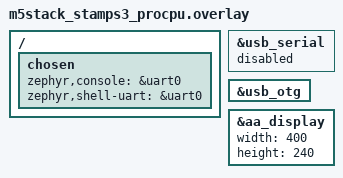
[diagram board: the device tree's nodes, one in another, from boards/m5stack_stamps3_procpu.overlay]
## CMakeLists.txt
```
# Copyright The Zephyr Project Contributors
# SPDX-License-Identifier: Apache-2.0

cmake_minimum_required(VERSION 3.28.0)
find_package(Zephyr REQUIRED HINTS $ENV{ZEPHYR_BASE})
project(android_auto)

include(${ZEPHYR_BASE}/samples/subsys/usb/common/common.cmake)

list(APPEND CMAKE_MODULE_PATH ${ZEPHYR_BASE}/modules/nanopb)
include(nanopb)

zephyr_nanopb_sources(app src/aa.proto)

target_sources(app PRIVATE
  src/aa_control.c
  src/aa_display.c
  src/aa_encoder.c
  src/aa_frame.c
  src/aa_input.c
  src/aa_session.c
  src/aa_tls.c
  src/aa_touch.c
  src/aa_video.c
  src/h264_ipcm.c
  src/main.c
  src/ui.c
  src/yuv.c
)

target_sources_ifdef(CONFIG_SAMPLE_AA_TRANSPORT_USB app PRIVATE
  src/aa_aoa.c
  src/aa_transport_usb.c
)
target_sources_ifdef(CONFIG_SAMPLE_AA_TRANSPORT_TCP app PRIVATE src/aa_transport_tcp.c)
target_sources_ifdef(CONFIG_SAMPLE_AA_SENSOR_CHANNEL app PRIVATE src/aa_sensor.c)

if(CONFIG_SAMPLE_AA_H264_DUMP)
  target_sources(app PRIVATE src/h264_dump.c)
  target_sources(native_simulator INTERFACE src/h264_dump_bottom.c)
endif()

# Embed the PEM credentials, NUL terminated by the including source file
set(gen_dir ${ZEPHYR_BINARY_DIR}/include/generated)
foreach(cred cert key)
  string(TOUPPER ${cred} cred_upper)
  set(cred_path "${CONFIG_SAMPLE_AA_${cred_upper}_FILE}")
  if(NOT IS_ABSOLUTE "${cred_path}")
    set(cred_path "${CMAKE_CURRENT_SOURCE_DIR}/${cred_path}")
  endif()
  generate_inc_file_for_target(app ${cred_path} ${gen_dir}/aa_${cred}.pem.inc)
endforeach()

if(CONFIG_SAMPLE_AA_DEMO_WIDGETS)
  set(LVGL_DIR ${ZEPHYR_LVGL_MODULE_DIR})
  target_include_directories(app PRIVATE ${LVGL_DIR}/demos/)
  target_sources(app PRIVATE
    ${LVGL_DIR}/demos/widgets/assets/img_clothes.c
    ${LVGL_DIR}/demos/widgets/assets/img_demo_widgets_avatar.c
    ${LVGL_DIR}/demos/widgets/assets/img_demo_widgets_needle.c
    ${LVGL_DIR}/demos/widgets/assets/img_lvgl_logo.c
    ${LVGL_DIR}/demos/widgets/lv_demo_widgets.c
    ${LVGL_DIR}/demos/widgets/lv_demo_widgets_analytics.c
    ${LVGL_DIR}/demos/widgets/lv_demo_widgets_components.c
    ${LVGL_DIR}/demos/widgets/lv_demo_widgets_profile.c
    ${LVGL_DIR}/demos/widgets/lv_demo_widgets_shop.c
  )
endif()
```

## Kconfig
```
# Copyright The Zephyr Project Contributors
# SPDX-License-Identifier: Apache-2.0

mainmenu "Android Auto accessory sample"

source "samples/subsys/usb/common/Kconfig.sample_usbd"

menu "Android Auto sample"

choice SAMPLE_AA_TRANSPORT
	prompt "Head unit transport"
	default SAMPLE_AA_TRANSPORT_USB if USB_DEVICE_STACK_NEXT
	default SAMPLE_AA_TRANSPORT_TCP

config SAMPLE_AA_TRANSPORT_USB
	bool "USB accessory"
	depends on USB_DEVICE_STACK_NEXT
	help
	  Enumerate as an Android device in accessory mode and talk to the head
	  unit over the accessory bulk endpoints.

config SAMPLE_AA_TRANSPORT_TCP
	bool "TCP"
	depends on NET_SOCKETS
	help
	  Wait for a head unit on a TCP port instead of USB. The Desktop Head
	  Unit of the Android SDK connects to localhost:5277 by default.

endchoice

config SAMPLE_AA_TCP_PORT
	int "TCP port"
	depends on SAMPLE_AA_TRANSPORT_TCP
	default 5277
	range 0 65535
	help
	  Port the head unit connects to. 0 lets the host pick a free port,
	  which is logged at startup.

if SAMPLE_AA_TRANSPORT_USB

config SAMPLE_AA_AOA_VID
	hex "Accessory mode vendor id"
	default 0x18d1
	help
	  Vendor id presented in accessory mode. Head units look for Google's
	  vendor id and the accessory product ids.

config SAMPLE_AA_AOA_PID
	hex "Accessory mode product id"
	default 0x2d00
	help
	  0x2d00 is accessory mode alone, 0x2d01 accessory mode with an ADB
	  interface, which this sample does not provide.

choice SAMPLE_AA_USB_START_MODE
	prompt "Accessory mode entry"
	default SAMPLE_AA_USB_ACCESSORY_AT_BOOT

config SAMPLE_AA_USB_ACCESSORY_AT_BOOT
	bool "Enumerate in accessory mode"
	help
	  Present the accessory vendor and product ids from the first
	  enumeration. A start request from the head unit still triggers a
	  re-enumeration.

config SAMPLE_AA_USB_ACCESSORY_ON_START
	bool "Enumerate with the Zephyr ids and switch on request"
	help
	  Enumerate with CONFIG_SAMPLE_USBD_VID and CONFIG_SAMPLE_USBD_PID and
	  only switch to the accessory ids when the head unit sends the
	  accessory start request, like an Android device does.

endchoice

config SAMPLE_AA_AOA_STRING_SIZE
	int "Accessory string buffer size"
	default 64
	range 8 256

config SAMPLE_AA_AOA_SWITCH_DELAY_MS
	int "Delay before re-enumerating after a start request (ms)"
	default 100

config SAMPLE_AA_USB_OUT_XFER_SIZE
	int "Bulk OUT transfer size"
	default 512
	range 64 4096

config SAMPLE_AA_USB_IN_XFER_SIZE
	int "Bulk IN transfer size"
	default 2048
	range 64 8192

config SAMPLE_AA_USB_RX_PIPE_SIZE
	int "Receive pipe size"
	default 8192

config SAMPLE_AA_USB_WRITE_TIMEOUT_MS
	int "Bulk IN buffer wait timeout (ms)"
	default 2000

config SAMPLE_AA_USB_START_DELAY_MS
	int "Delay before the USB device is enabled (ms)"
	default 0
	help
	  On SoCs whose USB PHY is shared between a serial or JTAG debug port
	  and the USB device controller, the debug port disappears once the
	  device is enabled. A delay keeps it reachable after every reset,
	  which leaves a window to enter the bootloader for reflashing.

endif # SAMPLE_AA_TRANSPORT_USB

config SAMPLE_AA_TX_CHUNK_SIZE
	int "Largest message fragment sent (bytes)"
	default 16384
	range 1024 16384
	help
	  Messages larger than this are fragmented. Must not exceed the Mbed
	  TLS output content length.

config SAMPLE_AA_RX_FRAME_SIZE
	int "Receive frame buffer size (bytes)"
	default 8256
	help
	  Must hold the largest TLS record the head unit sends, that is the
	  Mbed TLS input content length plus the record overhead.

config SAMPLE_AA_RX_MSG_SIZE
	int "Reassembly buffer for fragmented messages (bytes)"
	default 4096

config SAMPLE_AA_SESSION_TIMEOUT_MS
	int "Session setup timeout (ms)"
	default 20000
	help
	  The link is dropped when the session does not reach the running
	  state within this time.

config SAMPLE_AA_PROTO_MINOR
	int "Protocol minor version announced to the head unit"
	default 1

config SAMPLE_AA_DEVICE_NAME
	string "Device name announced in service discovery"
	default "Zephyr"

config SAMPLE_AA_DEVICE_BRAND
	string "Device brand announced in service discovery"
	default "Zephyr Project"

config SAMPLE_AA_RX_THREAD_PRIORITY
	int "Receive thread priority"
	default 5

config SAMPLE_AA_RX_STACK_SIZE
	int "Receive thread stack size"
	default 8192 if 64BIT
	default 6144

config SAMPLE_AA_VIDEO_THREAD_PRIORITY
	int "Video thread priority"
	default 7

config SAMPLE_AA_VIDEO_STACK_SIZE
	int "Video thread stack size"
	default 8192 if 64BIT
	default 4096

config SAMPLE_AA_INPUT_KEYS
	bool "Bind head unit keys and report them as input key events"
	default y

config SAMPLE_AA_SENSOR_CHANNEL
	bool "Subscribe to the night mode sensor and switch the theme"

config SAMPLE_AA_CERT_FILE
	string "Certificate presented to the head unit (PEM)"
	default "certs/aa_cert.pem"
	help
	  Relative paths are resolved from the sample directory. Head units
	  that verify the phone certificate need a certificate issued by
	  Google; the bundled one is self-signed.

config SAMPLE_AA_KEY_FILE
	string "Private key of the certificate (PEM)"
	default "certs/aa_key.pem"

config SAMPLE_AA_TLS_DEBUG_LEVEL
	int "Mbed TLS debug threshold"
	depends on MBEDTLS_DEBUG
	default 1
	range 0 5

menu "Video"

choice SAMPLE_AA_VIDEO_RESOLUTION
	prompt "Stream resolution"
	default SAMPLE_AA_VIDEO_800X480

config SAMPLE_AA_VIDEO_800X480
	bool "800x480"

config SAMPLE_AA_VIDEO_1280X720
	bool "1280x720"

endchoice

config SAMPLE_AA_VIDEO_WIDTH
	int
	default 1280 if SAMPLE_AA_VIDEO_1280X720
	default 800

config SAMPLE_AA_VIDEO_HEIGHT
	int
	default 720 if SAMPLE_AA_VIDEO_1280X720
	default 480

choice SAMPLE_AA_VIDEO_FPS
	prompt "Frame rate requested from the head unit"
	default SAMPLE_AA_VIDEO_FPS_30

config SAMPLE_AA_VIDEO_FPS_30
	bool "30 fps"

config SAMPLE_AA_VIDEO_FPS_60
	bool "60 fps"

endchoice

config SAMPLE_AA_MAX_FPS
	int "Maximum number of pictures sent per second"
	default 30
	range 1 60

config SAMPLE_AA_MAX_MBS_PER_FRAME
	int "Maximum coded macroblocks per P picture (0 = unlimited)"
	default 0
	help
	  Large redraws are spread over several pictures instead of one long
	  transfer when this is set.

config SAMPLE_AA_MAX_KBPS
	int "Output rate cap in kbit/s (0 = link speed)"
	default 0

config SAMPLE_AA_VIDEO_MAX_UNACKED_CAP
	int "Upper bound for unacknowledged media messages"
	default 4
	range 1 16

config SAMPLE_AA_VIDEO_ACK_TIMEOUT_MS
	int "Media acknowledgment timeout (ms)"
	default 3000

config SAMPLE_AA_VIDEO_CODEC_CONFIG_MSG
	bool "Send the parameter sets in a separate media message first"
	help
	  The parameter sets are always part of every IDR picture; this
	  additionally sends them once in a media message without timestamp
	  when streaming starts.

config SAMPLE_AA_H264_LEVEL_IDC
	int "H.264 level_idc"
	default 31

config SAMPLE_AA_H264_SLICE_ROWS
	int "Macroblock rows per slice (0 = one slice per picture)"
	default 1
	range 0 68

config SAMPLE_AA_H264_OUT_BUF_SIZE
	int "Encoder staging buffer (bytes)"
	default 2048
	range 256 16384

config SAMPLE_AA_DIRTY_COMPARE
	bool "Only send macroblocks whose pixels changed"
	default y
	help
	  Compare the rendered pixels with the framebuffer before marking a
	  macroblock dirty. LVGL redraws whole areas; the comparison keeps
	  unchanged macroblocks off the link.

choice SAMPLE_AA_PIXEL_FORMAT
	prompt "Framebuffer pixel format"
	default SAMPLE_AA_PIXEL_RGB565

config SAMPLE_AA_PIXEL_RGB565
	bool "RGB565"
	depends on LV_COLOR_DEPTH_16

config SAMPLE_AA_PIXEL_L8
	bool "8-bit grayscale"
	depends on LV_COLOR_DEPTH_8
	help
	  Halves the framebuffer size at the cost of colour, for boards
	  without external RAM.

endchoice

config SAMPLE_AA_FB_IN_EXT_RAM
	bool "Place the framebuffer in external RAM"
	depends on ESP_SPIRAM
	default y

config SAMPLE_AA_FB_SECTION
	string "Framebuffer linker section"
	depends on SAMPLE_AA_FB_IN_EXT_RAM
	default ".ext_ram.bss"

config SAMPLE_AA_H264_DUMP
	bool "Dump the stream and reference pictures to host files"
	depends on ARCH_POSIX
	help
	  Writes the H.264 stream and, for every picture, the framebuffer as
	  I420 so that a host decoder can be checked for bit-exact output.

config SAMPLE_AA_H264_DUMP_PATH
	string "H.264 dump file"
	depends on SAMPLE_AA_H264_DUMP
	default "aa_video.h264"

config SAMPLE_AA_H264_SELFTEST
	bool "Encode and check a few pictures at boot"

config SAMPLE_AA_DEMO_WIDGETS
	bool "Show the LVGL widgets demo instead of the sample screen"
	select LV_USE_DEMO_WIDGETS
	select LV_FONT_MONTSERRAT_12
	select LV_FONT_MONTSERRAT_14
	select LV_FONT_MONTSERRAT_16
	select LV_FONT_MONTSERRAT_18
	select LV_FONT_MONTSERRAT_20
	select LV_FONT_MONTSERRAT_22
	select LV_FONT_MONTSERRAT_24

endmenu # Video

module = SAMPLE_AA
module-str = Android Auto sample
source "subsys/logging/Kconfig.template.log_config"

endmenu # Android Auto sample

source "Kconfig.zephyr"
```

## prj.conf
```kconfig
CONFIG_LOG=y
CONFIG_MAIN_STACK_SIZE=4096

CONFIG_INPUT=y
CONFIG_DISPLAY=y

CONFIG_LVGL=y
CONFIG_LV_Z_MEM_POOL_SIZE=32768
CONFIG_LV_Z_VDB_SIZE=10
CONFIG_LV_Z_RUN_LVGL_ON_WORKQUEUE=y
CONFIG_LV_Z_LVGL_MUTEX=y
CONFIG_LV_Z_LVGL_WORKQUEUE_STACK_SIZE=8192
CONFIG_LV_FONT_MONTSERRAT_14=y
CONFIG_LV_FONT_MONTSERRAT_24=y
CONFIG_LV_USE_THEME_DEFAULT=y

CONFIG_PSA_CRYPTO=y
CONFIG_MBEDTLS=y
CONFIG_MBEDTLS_ENABLE_HEAP=y
CONFIG_MBEDTLS_HEAP_SIZE=49152
CONFIG_MBEDTLS_CIPHERSUITE_TLS_ECDHE_ECDSA_WITH_AES_128_GCM_SHA256=y
CONFIG_MBEDTLS_SSL_IN_CONTENT_LEN=8192
CONFIG_MBEDTLS_SSL_OUT_CONTENT_LEN=16384
CONFIG_MBEDTLS_PEM_PARSE_C=y
CONFIG_MBEDTLS_ECP_NIST_OPTIM=y
CONFIG_ENTROPY_GENERATOR=y

CONFIG_NANOPB=y
```

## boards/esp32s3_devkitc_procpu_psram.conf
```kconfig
CONFIG_USB_DEVICE_STACK_NEXT=y
CONFIG_SAMPLE_AA_TRANSPORT_USB=y
CONFIG_SAMPLE_USBD_PID=0x0014
CONFIG_SAMPLE_USBD_PRODUCT="Android Auto accessory"
CONFIG_USBD_LOG_LEVEL_WRN=y
CONFIG_UDC_DRIVER_LOG_LEVEL_WRN=y

CONFIG_SAMPLE_AA_TX_CHUNK_SIZE=8192
CONFIG_SAMPLE_AA_RX_FRAME_SIZE=4160
CONFIG_MBEDTLS_SSL_OUT_CONTENT_LEN=8192
CONFIG_MBEDTLS_SSL_IN_CONTENT_LEN=4096
CONFIG_MBEDTLS_HEAP_SIZE=40960

# External RAM holds the full-resolution framebuffer and the LVGL buffers
CONFIG_ESP_SPIRAM=y
CONFIG_LV_Z_VDB_CUSTOM_SECTION=y
CONFIG_LV_Z_MEMORY_POOL_CUSTOM_SECTION=y
CONFIG_LV_Z_MEM_POOL_SIZE=131072
CONFIG_LV_Z_VDB_SIZE=10
CONFIG_SPIRAM_MODE_QUAD=y
```

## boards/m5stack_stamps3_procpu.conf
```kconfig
CONFIG_USB_DEVICE_STACK_NEXT=y
CONFIG_SAMPLE_AA_TRANSPORT_USB=y
CONFIG_SAMPLE_USBD_PID=0x0014
CONFIG_SAMPLE_USBD_PRODUCT="Android Auto accessory"
CONFIG_USBD_LOG_LEVEL_WRN=y
CONFIG_UDC_DRIVER_LOG_LEVEL_WRN=y

CONFIG_SAMPLE_AA_TX_CHUNK_SIZE=8192
CONFIG_SAMPLE_AA_RX_FRAME_SIZE=4160
CONFIG_MBEDTLS_SSL_OUT_CONTENT_LEN=8192
CONFIG_MBEDTLS_SSL_IN_CONTENT_LEN=4096
CONFIG_MBEDTLS_HEAP_SIZE=40960

# No external RAM: half-resolution grayscale framebuffer (see the README)
CONFIG_LV_COLOR_DEPTH_8=y
CONFIG_SAMPLE_AA_PIXEL_L8=y
CONFIG_LV_Z_MEM_POOL_SIZE=32768
CONFIG_LV_Z_VDB_SIZE=10
```

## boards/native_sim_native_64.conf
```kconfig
CONFIG_SAMPLE_AA_TRANSPORT_TCP=y

CONFIG_NETWORKING=y
CONFIG_NET_IPV4=y
CONFIG_NET_IPV6=n
CONFIG_NET_SOCKETS=y
CONFIG_NET_SOCKETS_OFFLOAD=y
CONFIG_NET_DRIVERS=y
CONFIG_NET_NATIVE_OFFLOADED_SOCKETS=y
CONFIG_ETH_NATIVE_TAP=n

CONFIG_MBEDTLS_HEAP_SIZE=65536
CONFIG_LV_Z_MEM_POOL_SIZE=131072
CONFIG_LV_Z_VDB_SIZE=25
```

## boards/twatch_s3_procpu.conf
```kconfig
CONFIG_USB_DEVICE_STACK_NEXT=y
CONFIG_SAMPLE_AA_TRANSPORT_USB=y
CONFIG_SAMPLE_USBD_PID=0x0014
CONFIG_SAMPLE_USBD_PRODUCT="Android Auto accessory"
CONFIG_USBD_LOG_LEVEL_WRN=y
CONFIG_UDC_DRIVER_LOG_LEVEL_WRN=y

CONFIG_SAMPLE_AA_TX_CHUNK_SIZE=8192
CONFIG_SAMPLE_AA_RX_FRAME_SIZE=4160
CONFIG_MBEDTLS_SSL_OUT_CONTENT_LEN=8192
CONFIG_MBEDTLS_SSL_IN_CONTENT_LEN=4096
CONFIG_MBEDTLS_HEAP_SIZE=40960

# External RAM holds the full-resolution framebuffer and the LVGL buffers
CONFIG_ESP_SPIRAM=y
CONFIG_LV_Z_VDB_CUSTOM_SECTION=y
CONFIG_LV_Z_MEMORY_POOL_CUSTOM_SECTION=y
CONFIG_LV_Z_MEM_POOL_SIZE=131072
CONFIG_LV_Z_VDB_SIZE=10
CONFIG_SPIRAM_MODE_OCT=y
CONFIG_LV_COLOR_16_SWAP=n

# The USB serial console shares the PHY with USB OTG: keep it for a few seconds after
# reset so that the boot log is visible and the bootloader stays reachable for flashing
CONFIG_SAMPLE_AA_USB_START_DELAY_MS=8000
```

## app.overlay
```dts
/*
 * Copyright The Zephyr Project Contributors
 * SPDX-License-Identifier: Apache-2.0
 */

#include <android_auto.dtsi>
```

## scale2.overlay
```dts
/*
 * Copyright The Zephyr Project Contributors
 * SPDX-License-Identifier: Apache-2.0
 */

/* Render at half the stream resolution, every pixel becomes a 2x2 block */
&aa_display {
	width = <400>;
	height = <240>;
};
```

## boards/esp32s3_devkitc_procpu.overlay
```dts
/*
 * Copyright The Zephyr Project Contributors
 * SPDX-License-Identifier: Apache-2.0
 */

#include <android_auto.dtsi>

/* Half-resolution framebuffer, every pixel becomes a 2x2 block in the stream */
&aa_display {
	width = <400>;
	height = <240>;
};
```

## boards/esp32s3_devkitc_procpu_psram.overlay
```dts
/*
 * Copyright The Zephyr Project Contributors
 * SPDX-License-Identifier: Apache-2.0
 */

#include <android_auto.dtsi>

/* Modules with 8 MB of PSRAM (N8R8) hold the full-resolution framebuffer */
&psram0 {
	size = <DT_SIZE_M(8)>;
};
```

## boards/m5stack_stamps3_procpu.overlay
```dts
/*
 * Copyright The Zephyr Project Contributors
 * SPDX-License-Identifier: Apache-2.0
 */

#include <android_auto.dtsi>

/* USB OTG takes over the USB PHY from the serial console, which moves to UART0 */
/ {
	chosen {
		zephyr,console = &uart0;
		zephyr,shell-uart = &uart0;
	};
};

&usb_serial {
	status = "disabled";
};

zephyr_udc0: &usb_otg {
	status = "okay";
};

/* Half-resolution framebuffer, every pixel becomes a 2x2 block in the stream */
&aa_display {
	width = <400>;
	height = <240>;
};
```

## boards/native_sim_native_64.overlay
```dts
/*
 * Copyright The Zephyr Project Contributors
 * SPDX-License-Identifier: Apache-2.0
 */

#include <android_auto.dtsi>

/* The SDL display and touch emulation are replaced by the virtual display */
&sdl_dc {
	status = "disabled";
};

&input_sdl_touch {
	status = "disabled";
};
```

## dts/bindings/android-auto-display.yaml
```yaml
# Copyright The Zephyr Project Contributors
# SPDX-License-Identifier: Apache-2.0

description: |
  Virtual display of the Android Auto accessory sample. What LVGL renders
  into it is streamed to the head unit as H.264 video. The width and height
  properties give the LVGL resolution; the stream resolution is set by
  CONFIG_SAMPLE_AA_VIDEO_WIDTH and CONFIG_SAMPLE_AA_VIDEO_HEIGHT and must be
  equal to or twice these values.

compatible: "android-auto-display"

include: display-controller.yaml
```

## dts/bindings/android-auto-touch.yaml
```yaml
# Copyright The Zephyr Project Contributors
# SPDX-License-Identifier: Apache-2.0

description: |
  Touch screen of the Android Auto accessory sample, fed by the touch events
  the head unit sends back for the streamed screen.

compatible: "android-auto-touch"

include: base.yaml
```

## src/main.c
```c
/*
 * Copyright The Zephyr Project Contributors
 * SPDX-License-Identifier: Apache-2.0
 */

#include <string.h>

#include <zephyr/device.h>
#include <zephyr/drivers/display.h>
#include <zephyr/kernel.h>
#include <zephyr/logging/log.h>

#include <lvgl.h>
#include <lvgl_zephyr.h>

#include "aa_display.h"
#include "aa_encoder.h"
#include "aa_session.h"
#include "aa_touch.h"
#include "h264_dump.h"
#include "ui.h"

LOG_MODULE_REGISTER(aa_main, CONFIG_SAMPLE_AA_LOG_LEVEL);

#ifdef CONFIG_SAMPLE_AA_H264_SELFTEST

/*
 * Boot-time check of the video pipeline: renders the screen, encodes an IDR
 * picture, injects a touch on the counter button, encodes the resulting P
 * picture and validates the Annex B structure of both.
 */

struct selftest_sink {
	uint32_t nal_count;
	uint32_t idr_slices;
	uint32_t p_slices;
	uint32_t sps;
	uint32_t pps;
	uint32_t epb_violations;
	size_t bytes;
	uint8_t last[3];
	uint32_t zeros;
	bool expect_header;
};

static struct selftest_sink st;

static void selftest_byte(struct selftest_sink *s, uint8_t b)
{
	/* Start codes are the only place where 00 00 0x (x <= 3) may occur */
	if (s->zeros >= 2U && b <= 0x03U) {
		if (b == 0x01U) {
			s->nal_count++;
			s->expect_header = true;
			s->zeros = 0U;
			return;
		}
		if (b != 0x00U) {
			s->epb_violations++;
		}
	}

	if (s->expect_header) {
		uint8_t type = b & 0x1FU;

		s->expect_header = false;
		if (type == 5U) {
			s->idr_slices++;
		} else if (type == 1U) {
			s->p_slices++;
		} else if (type == 7U) {
			s->sps++;
		} else if (type == 8U) {
			s->pps++;
		}
	}

	if (b == 0x00U) {
		s->zeros++;
	} else {
		s->zeros = 0U;
	}
}

static int selftest_sink_cb(void *ctx, const uint8_t *data, size_t len)
{
	struct selftest_sink *s = ctx;

	for (size_t i = 0; i < len; i++) {
		selftest_byte(s, data[i]);
	}
	s->bytes += len;

	return aa_dump_h264(data, len);
}

static int selftest_picture(bool idr, struct aa_frame_plan *plan)
{
	int ret;

	lvgl_lock();
	lv_refr_now(NULL);
	lvgl_unlock();

	ret = aa_encoder_prepare(idr, plan);
	if (ret != 0) {
		LOG_ERR("Self-test: nothing to encode (%d)", ret);
		return ret;
	}

	memset(&st, 0, sizeof(st));
	ret = aa_encoder_emit(plan, selftest_sink_cb, &st);
	if (ret != 0) {
		LOG_ERR("Self-test: encoding failed (%d)", ret);
		return ret;
	}

	if (st.bytes != plan->au_len || st.epb_violations != 0U) {
		LOG_ERR("Self-test: %zu bytes for %zu measured, %u forbidden sequences",
			st.bytes, plan->au_len, st.epb_violations);
		return -EIO;
	}

	return aa_dump_yuv_frame();
}

static void selftest(void)
{
	const struct aa_display_geometry *g = aa_display_geometry();
	static struct aa_frame_plan plan;
	size_t idr_bytes;
	uint32_t idr_nals;
	uint16_t tap_x;
	uint16_t tap_y;
	int ret;

	ret = selftest_picture(true, &plan);
	if (ret != 0) {
		return;
	}
	idr_bytes = st.bytes;
	idr_nals = st.nal_count;
	if (st.sps != 1U || st.pps != 1U || st.idr_slices == 0U || plan.coded_mbs != AA_MBS) {
		LOG_ERR("Self-test: bad IDR picture (sps %u pps %u slices %u)", st.sps, st.pps,
			st.idr_slices);
		return;
	}

	/* Press the counter button */
	lvgl_lock();
	ret = aa_ui_get_tap_target(&tap_x, &tap_y);
	lvgl_unlock();
	if (ret != 0) {
		LOG_ERR("Self-test: no button to press");
		return;
	}
	tap_x *= g->scale;
	tap_y *= g->scale;
	(void)aa_touch_report(tap_x, tap_y, true);
	k_sleep(K_MSEC(150));
	(void)aa_touch_report(tap_x, tap_y, false);
	k_sleep(K_MSEC(300));

	ret = selftest_picture(false, &plan);
	if (ret != 0) {
		return;
	}
	if (plan.idr || st.p_slices == 0U || plan.coded_mbs == 0U) {
		LOG_ERR("Self-test: bad P picture (%u macroblocks)", plan.coded_mbs);
		return;
	}

	aa_ui_set_night(true);
	k_sleep(K_MSEC(700));
	(void)selftest_picture(false, &plan);
	aa_ui_set_night(false);

	LOG_INF("aa: video self-test OK idr=%zu nals=%u p=%zu mbs=%u", idr_bytes, idr_nals,
		st.bytes, plan.coded_mbs);
}
#endif /* CONFIG_SAMPLE_AA_H264_SELFTEST */

int main(void)
{
	const struct device *display = DEVICE_DT_GET(DT_CHOSEN(zephyr_display));
	int ret;

	if (!device_is_ready(display)) {
		LOG_ERR("Display not ready");
		return 0;
	}

	(void)display_blanking_off(display);

	lvgl_lock();
	ret = aa_ui_init();
	lvgl_unlock();
	if (ret != 0) {
		LOG_ERR("UI init failed (%d)", ret);
		return 0;
	}

	ret = aa_encoder_init();
	if (ret != 0) {
		LOG_ERR("Encoder init failed (%d)", ret);
		return 0;
	}

	(void)aa_dump_open();

#ifdef CONFIG_SAMPLE_AA_H264_SELFTEST
	selftest();
#endif

	ret = aa_session_start();
	if (ret != 0) {
		LOG_ERR("Session start failed (%d)", ret);
	}

	return 0;
}
```

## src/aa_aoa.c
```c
/*
 * Copyright The Zephyr Project Contributors
 * SPDX-License-Identifier: Apache-2.0
 */

#include "aa_aoa.h"

#include <errno.h>
#include <string.h>

#include <zephyr/kernel.h>
#include <zephyr/logging/log.h>
#include <zephyr/sys/util.h>

LOG_MODULE_REGISTER(aa_aoa, CONFIG_SAMPLE_AA_LOG_LEVEL);

/*
 * Android Open Accessory protocol, device side. The head unit acts as the
 * accessory: it asks for the protocol version, sends its identity strings and
 * requests accessory mode, after which the device re-enumerates with Google's
 * accessory vendor and product ids.
 */

#define AOA_REQ_GET_PROTOCOL 51U
#define AOA_REQ_SEND_STRING  52U
#define AOA_REQ_START        53U

#define AOA_PROTOCOL_VERSION 2U
#define AOA_STRING_COUNT     6U

static const char *const aoa_string_names[AOA_STRING_COUNT] = {
	"manufacturer", "model", "description", "version", "uri", "serial",
};

static char aoa_strings[AOA_STRING_COUNT][CONFIG_SAMPLE_AA_AOA_STRING_SIZE];
static struct usbd_context *aoa_ctx;
static struct k_work_delayable switch_work;

static struct net_buf *aoa_get_protocol(const struct usbd_context *const ctx,
					const struct usb_setup_packet *const setup)
{
	struct net_buf *buf;

	if (setup->RequestType.recipient != USB_REQTYPE_RECIPIENT_DEVICE) {
		return NULL;
	}

	buf = usbd_ep_ctrl_data_in_alloc(ctx, MIN(setup->wLength, sizeof(uint16_t)));
	if (buf == NULL) {
		return NULL;
	}

	net_buf_add_le16(buf, AOA_PROTOCOL_VERSION);
	LOG_INF("Accessory protocol version requested");

	return buf;
}

static int aoa_send_string(const struct usbd_context *const ctx,
			   const struct usb_setup_packet *const setup,
			   const struct net_buf *const buf)
{
	uint16_t idx = setup->wIndex;
	size_t len;

	if (setup->RequestType.recipient != USB_REQTYPE_RECIPIENT_DEVICE ||
	    idx >= AOA_STRING_COUNT || setup->wLength > CONFIG_SAMPLE_AA_AOA_STRING_SIZE) {
		return -ENOTSUP;
	}

	if (buf == NULL) {
		/* Accept the data stage */
		return 0;
	}

	len = MIN(buf->len, CONFIG_SAMPLE_AA_AOA_STRING_SIZE - 1U);
	memcpy(aoa_strings[idx], buf->data, len);
	aoa_strings[idx][len] = '\0';
	LOG_INF("Accessory %s: \"%s\"", aoa_string_names[idx], aoa_strings[idx]);

	return 0;
}

static int aoa_start(const struct usbd_context *const ctx,
		     const struct usb_setup_packet *const setup, const struct net_buf *const buf)
{
	if (setup->RequestType.recipient != USB_REQTYPE_RECIPIENT_DEVICE) {
		return -ENOTSUP;
	}

	LOG_INF("Accessory mode requested, re-enumerating");
	(void)k_work_schedule(&switch_work, K_MSEC(CONFIG_SAMPLE_AA_AOA_SWITCH_DELAY_MS));

	return 0;
}

USBD_VREQUEST_DEFINE(aoa_vreq_get_protocol, AOA_REQ_GET_PROTOCOL, aoa_get_protocol, NULL);
USBD_VREQUEST_DEFINE(aoa_vreq_send_string, AOA_REQ_SEND_STRING, NULL, aoa_send_string);
USBD_VREQUEST_DEFINE(aoa_vreq_start, AOA_REQ_START, NULL, aoa_start);

static void switch_work_handler(struct k_work *work)
{
	int ret;

	ARG_UNUSED(work);

	ret = usbd_disable(aoa_ctx);
	if (ret != 0 && ret != -EALREADY) {
		LOG_ERR("Failed to detach (%d)", ret);
		return;
	}

	(void)usbd_device_set_vid(aoa_ctx, CONFIG_SAMPLE_AA_AOA_VID);
	(void)usbd_device_set_pid(aoa_ctx, CONFIG_SAMPLE_AA_AOA_PID);

	k_sleep(K_MSEC(CONFIG_SAMPLE_AA_AOA_SWITCH_DELAY_MS));

	ret = usbd_enable(aoa_ctx);
	if (ret != 0) {
		LOG_ERR("Failed to attach in accessory mode (%d)", ret);
	}
}

int aa_aoa_register(struct usbd_context *uds_ctx)
{
	struct usbd_vreq_node *const nodes[] = {
		&aoa_vreq_get_protocol,
		&aoa_vreq_send_string,
		&aoa_vreq_start,
	};

	aoa_ctx = uds_ctx;
	k_work_init_delayable(&switch_work, switch_work_handler);

	for (size_t i = 0; i < ARRAY_SIZE(nodes); i++) {
		int ret = usbd_device_register_vreq(uds_ctx, nodes[i]);

		if (ret != 0) {
			LOG_ERR("Failed to register vendor request %u (%d)", nodes[i]->code, ret);
			return ret;
		}
	}

	return 0;
}
```

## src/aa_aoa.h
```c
/*
 * Copyright The Zephyr Project Contributors
 * SPDX-License-Identifier: Apache-2.0
 */

#ifndef SAMPLES_SUBSYS_USB_ANDROID_AUTO_SRC_AA_AOA_H_
#define SAMPLES_SUBSYS_USB_ANDROID_AUTO_SRC_AA_AOA_H_

#include <zephyr/usb/usbd.h>

/**
 * @brief Register the Android Open Accessory vendor requests.
 *
 * Must be called before usbd_init().
 *
 * @retval 0 Success.
 * @return Negative errno from the USB device stack.
 */
int aa_aoa_register(struct usbd_context *uds_ctx);

#endif /* SAMPLES_SUBSYS_USB_ANDROID_AUTO_SRC_AA_AOA_H_ */
```

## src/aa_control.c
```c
/*
 * Copyright The Zephyr Project Contributors
 * SPDX-License-Identifier: Apache-2.0
 */

#include "aa_control.h"

#include <string.h>

#include <zephyr/kernel.h>
#include <zephyr/logging/log.h>
#include <zephyr/sys/byteorder.h>
#include <zephyr/sys/util.h>

#include "src/aa.pb.h"
#include "aa_display.h"
#include "aa_frame.h"
#include "aa_ids.h"
#include "aa_session.h"
#include "aa_tls.h"
#include "aa_transport.h"
#include "ui.h"

LOG_MODULE_REGISTER(aa_control, CONFIG_SAMPLE_AA_LOG_LEVEL);

/*
 * Control channel: version exchange, TLS handshake transport, authentication,
 * service discovery, keep-alive and shutdown.
 */

#if defined(CONFIG_SAMPLE_AA_VIDEO_1280X720)
#define AA_WANTED_RESOLUTION AA_VIDEO_RESOLUTION_1280x720
#else
#define AA_WANTED_RESOLUTION AA_VIDEO_RESOLUTION_800x480
#endif

#if defined(CONFIG_SAMPLE_AA_VIDEO_FPS_60)
#define AA_WANTED_FPS AA_VIDEO_FPS_60
#else
#define AA_WANTED_FPS AA_VIDEO_FPS_30
#endif

/* Service discovery responses are the largest messages the head unit sends */
static ServiceDiscoveryResponse sd_response;

static int send_version_response(void)
{
	uint8_t body[6];

	sys_put_be16(AA_PROTO_MAJOR, &body[0]);
	sys_put_be16(CONFIG_SAMPLE_AA_PROTO_MINOR, &body[2]);
	sys_put_be16(0U, &body[4]); /* status: match */

	return aa_msg_send(AA_CHANNEL_CONTROL, false, AA_CTRL_VERSION_RESPONSE, body, sizeof(body));
}

static int send_service_discovery_request(void)
{
	ServiceDiscoveryRequest req = ServiceDiscoveryRequest_init_zero;
	uint8_t buf[80];
	int len;

	req.has_device_name = true;
	strncpy(req.device_name, CONFIG_SAMPLE_AA_DEVICE_NAME, sizeof(req.device_name) - 1U);
	req.has_label_text = true;
	strncpy(req.label_text, CONFIG_SAMPLE_AA_DEVICE_BRAND, sizeof(req.label_text) - 1U);

	len = aa_pb_encode(buf, sizeof(buf), ServiceDiscoveryRequest_fields, &req);
	if (len < 0) {
		return len;
	}

	return aa_msg_send(AA_CHANNEL_CONTROL, false, AA_CTRL_SERVICE_DISCOVERY_REQUEST, buf,
			   (size_t)len);
}

static void select_video_config(struct aa_session *s, const AVChannel *av)
{
	s->video_config_idx = 0U;

	for (pb_size_t i = 0; i < av->video_configs_count; i++) {
		const VideoConfig *cfg = &av->video_configs[i];

		LOG_INF("  video config %u: resolution %d fps %d margins %ux%u dpi %u", i,
			cfg->video_resolution, cfg->video_fps, cfg->margin_width,
			cfg->margin_height, cfg->dpi);
	}

	for (pb_size_t i = 0; i < av->video_configs_count; i++) {
		const VideoConfig *cfg = &av->video_configs[i];

		if (cfg->video_resolution == AA_WANTED_RESOLUTION &&
		    (!cfg->has_video_fps || cfg->video_fps == AA_WANTED_FPS)) {
			s->video_config_idx = i;
			return;
		}
	}

	for (pb_size_t i = 0; i < av->video_configs_count; i++) {
		if (av->video_configs[i].video_resolution == AA_WANTED_RESOLUTION) {
			s->video_config_idx = i;
			return;
		}
	}

	LOG_WRN("Head unit does not offer %ux%u, using video config 0", AA_VIDEO_WIDTH,
		AA_VIDEO_HEIGHT);
}

static void on_service_discovery_response(const uint8_t *body, size_t len)
{
	struct aa_session *s = aa_session_get();

	memset(&sd_response, 0, sizeof(sd_response));
	if (aa_pb_decode(body, len, ServiceDiscoveryResponse_fields, &sd_response) != 0) {
		aa_session_abort("bad service discovery response");
		return;
	}

	LOG_INF("Head unit \"%s\", car model \"%s\", %u channels",
		sd_response.has_head_unit_name ? sd_response.head_unit_name : "?",
		sd_response.has_car_model ? sd_response.car_model : "?",
		sd_response.channels_count);

	for (pb_size_t i = 0; i < sd_response.channels_count; i++) {
		const ChannelDescriptor *ch = &sd_response.channels[i];
		uint8_t id = (uint8_t)ch->channel_id;

		if (ch->has_av_channel && ch->av_channel.stream_type == AA_STREAM_TYPE_VIDEO) {
			LOG_INF("Channel %u: video", id);
			if (!s->has_video) {
				s->has_video = true;
				s->video_ch = id;
				select_video_config(s, &ch->av_channel);
			}
		} else if (ch->has_input_channel) {
			const InputChannel *in = &ch->input_channel;

			LOG_INF("Channel %u: input, touch screen %ux%u", id,
				in->has_touch_screen_config ? in->touch_screen_config.width : 0U,
				in->has_touch_screen_config ? in->touch_screen_config.height : 0U);
			if (!s->has_input) {
				s->has_input = true;
				s->input_ch = id;
				if (in->has_touch_screen_config) {
					s->touch_width = (uint16_t)in->touch_screen_config.width;
					s->touch_height = (uint16_t)in->touch_screen_config.height;
				}
			}
		} else if (ch->has_sensor_channel) {
			LOG_INF("Channel %u: sensors (%u)", id, ch->sensor_channel.sensors_count);
			if (IS_ENABLED(CONFIG_SAMPLE_AA_SENSOR_CHANNEL) && !s->has_sensor) {
				s->has_sensor = true;
				s->sensor_ch = id;
			}
		} else if (ch->has_av_channel) {
			LOG_INF("Channel %u: audio (type %d)", id, ch->av_channel.audio_type);
		} else {
			LOG_INF("Channel %u: other", id);
		}
	}

	if (!s->has_video) {
		aa_session_abort("head unit offers no video channel");
		return;
	}

	if (s->touch_width == 0U || s->touch_height == 0U) {
		s->touch_width = AA_VIDEO_WIDTH;
		s->touch_height = AA_VIDEO_HEIGHT;
	}

	if (aa_session_open_channels() != 0) {
		aa_session_abort("channel open request failed");
	}
}

static void on_ping_request(const uint8_t *body, size_t len)
{
	PingRequest req = PingRequest_init_zero;
	PingResponse rsp = PingResponse_init_zero;
	uint8_t buf[16];
	int n;

	if (aa_pb_decode(body, len, PingRequest_fields, &req) != 0) {
		return;
	}

	rsp.has_timestamp = true;
	rsp.timestamp = req.timestamp;
	n = aa_pb_encode(buf, sizeof(buf), PingResponse_fields, &rsp);
	if (n >= 0) {
		(void)aa_msg_send(AA_CHANNEL_CONTROL, false, AA_CTRL_PING_RESPONSE, buf, (size_t)n);
	}
}

static void on_navigation_focus_request(const uint8_t *body, size_t len)
{
	NavigationFocusRequest req = NavigationFocusRequest_init_zero;
	NavigationFocusResponse rsp = NavigationFocusResponse_init_zero;
	uint8_t buf[16];
	int n;

	if (aa_pb_decode(body, len, NavigationFocusRequest_fields, &req) != 0) {
		return;
	}

	rsp.has_type = true;
	rsp.type = req.type;
	n = aa_pb_encode(buf, sizeof(buf), NavigationFocusResponse_fields, &rsp);
	if (n >= 0) {
		(void)aa_msg_send(AA_CHANNEL_CONTROL, false, AA_CTRL_NAVIGATION_FOCUS_RESPONSE, buf,
				  (size_t)n);
	}
}

void aa_control_handle(uint16_t msg_id, const uint8_t *body, size_t len)
{
	struct aa_session *s = aa_session_get();
	int ret;

	switch (msg_id) {
	case AA_CTRL_VERSION_REQUEST:
		if (s->state != AA_STATE_WAIT_VERSION) {
			/* A head unit that went away silently (USB stays configured) came back */
			LOG_WRN("Version request during a session, starting over");
			aa_session_restart();
		}
		if (len >= 4U) {
			s->hu_major = sys_get_be16(&body[0]);
			s->hu_minor = sys_get_be16(&body[2]);
		}
		LOG_INF("Head unit protocol version %u.%u", s->hu_major, s->hu_minor);
		if (send_version_response() != 0) {
			aa_session_abort("version response failed");
			return;
		}
		aa_session_set_state(AA_STATE_HANDSHAKE);
		break;

	case AA_CTRL_SSL_HANDSHAKE:
		ret = aa_tls_handshake_input(body, len);
		if (ret == 0) {
			aa_session_set_state(AA_STATE_WAIT_AUTH);
		} else if (ret != -EAGAIN) {
			aa_session_abort("TLS handshake failed");
		}
		break;

	case AA_CTRL_AUTH_COMPLETE: {
		AuthCompleteIndication ind = AuthCompleteIndication_init_zero;

		if (aa_pb_decode(body, len, AuthCompleteIndication_fields, &ind) != 0 ||
		    (ind.has_status && ind.status != AA_STATUS_OK)) {
			aa_session_abort("authentication refused");
			return;
		}
		if (!aa_tls_handshake_done()) {
			aa_session_abort("auth complete before the handshake");
			return;
		}
		LOG_INF("Authenticated, encryption on");
		aa_frame_set_encrypted(true);
		aa_ui_set_link_state(AA_UI_LINK_SECURE);
		if (send_service_discovery_request() != 0) {
			aa_session_abort("service discovery request failed");
			return;
		}
		aa_session_set_state(AA_STATE_WAIT_SERVICE_DISCOVERY);
		break;
	}

	case AA_CTRL_SERVICE_DISCOVERY_RESPONSE:
		on_service_discovery_response(body, len);
		break;

	case AA_CTRL_PING_REQUEST:
		on_ping_request(body, len);
		break;

	case AA_CTRL_PING_RESPONSE:
		break;

	case AA_CTRL_NAVIGATION_FOCUS_REQUEST:
		on_navigation_focus_request(body, len);
		break;

	case AA_CTRL_SHUTDOWN_REQUEST:
		LOG_INF("Head unit requested shutdown");
		(void)aa_msg_send(AA_CHANNEL_CONTROL, false, AA_CTRL_SHUTDOWN_RESPONSE, NULL, 0U);
		aa_session_set_state(AA_STATE_SHUTDOWN);
		aa_session_abort("shutdown");
		break;

	case AA_CTRL_VOICE_SESSION_REQUEST:
	case AA_CTRL_AUDIO_FOCUS_REQUEST:
	case AA_CTRL_AUDIO_FOCUS_RESPONSE:
	case AA_CTRL_NAVIGATION_FOCUS_RESPONSE:
		LOG_INF("Ignoring control message 0x%04x", msg_id);
		break;

	default:
		LOG_WRN("Unknown control message 0x%04x (%zu bytes)", msg_id, len);
		break;
	}
}
```

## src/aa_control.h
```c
/*
 * Copyright The Zephyr Project Contributors
 * SPDX-License-Identifier: Apache-2.0
 */

#ifndef SAMPLES_SUBSYS_USB_ANDROID_AUTO_SRC_AA_CONTROL_H_
#define SAMPLES_SUBSYS_USB_ANDROID_AUTO_SRC_AA_CONTROL_H_

#include <stddef.h>
#include <stdint.h>

/** @brief Handle a message received on the control channel. */
void aa_control_handle(uint16_t msg_id, const uint8_t *body, size_t len);

#endif /* SAMPLES_SUBSYS_USB_ANDROID_AUTO_SRC_AA_CONTROL_H_ */
```

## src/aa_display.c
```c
/*
 * Copyright The Zephyr Project Contributors
 * SPDX-License-Identifier: Apache-2.0
 */

#define DT_DRV_COMPAT android_auto_display

#include "aa_display.h"

#include <errno.h>
#include <string.h>

#include <zephyr/device.h>
#include <zephyr/drivers/display.h>
#include <zephyr/logging/log.h>
#include <zephyr/sys/util.h>

LOG_MODULE_REGISTER(aa_display, CONFIG_SAMPLE_AA_LOG_LEVEL);

/*
 * Virtual display: LVGL renders into a framebuffer kept here; the encoder
 * converts changed 16x16 stream macroblocks from it on demand. With a
 * framebuffer half the stream size every framebuffer pixel becomes a 2x2
 * block in the stream.
 */

#define AA_LV_W     DT_INST_PROP(0, width)
#define AA_LV_H     DT_INST_PROP(0, height)
#define AA_SCALE    (AA_VIDEO_WIDTH / AA_LV_W)
#define AA_BPP      (IS_ENABLED(CONFIG_SAMPLE_AA_PIXEL_L8) ? 1U : 2U)
/* Framebuffer pixels per macroblock edge */
#define AA_MB_LV_PX (16U / AA_SCALE)

BUILD_ASSERT(AA_VIDEO_WIDTH % 16 == 0 && AA_VIDEO_HEIGHT % 16 == 0,
	     "Stream resolution must be a multiple of 16");
BUILD_ASSERT(AA_SCALE == 1 || AA_SCALE == 2, "Framebuffer must be the stream size or half of it");
BUILD_ASSERT(AA_LV_W * AA_SCALE == AA_VIDEO_WIDTH && AA_LV_H * AA_SCALE == AA_VIDEO_HEIGHT,
	     "Framebuffer and stream resolutions do not match");

#ifdef CONFIG_SAMPLE_AA_FB_IN_EXT_RAM
#define AA_FB_SECTION __attribute__((section(CONFIG_SAMPLE_AA_FB_SECTION)))
#else
#define AA_FB_SECTION
#endif

static uint8_t aa_fb[AA_LV_W * AA_LV_H * AA_BPP] AA_FB_SECTION __aligned(32);
static ATOMIC_DEFINE(aa_dirty, AA_MBS);
static K_SEM_DEFINE(aa_frame_sem, 0, 1);
static atomic_t aa_dirty_since_frame;

static const struct aa_display_geometry aa_geometry = {
	.lv_width = AA_LV_W,
	.lv_height = AA_LV_H,
	.width = AA_VIDEO_WIDTH,
	.height = AA_VIDEO_HEIGHT,
	.scale = AA_SCALE,
	.bpp = AA_BPP,
	.mbs_x = AA_MBS_X,
	.mbs_y = AA_MBS_Y,
};

const struct aa_display_geometry *aa_display_geometry(void)
{
	return &aa_geometry;
}

const uint8_t *aa_display_framebuffer(void)
{
	return aa_fb;
}

atomic_t *aa_display_dirty(void)
{
	return aa_dirty;
}

int aa_display_wait_frame(k_timeout_t timeout)
{
	if (k_sem_take(&aa_frame_sem, timeout) != 0) {
		return -EAGAIN;
	}

	return 0;
}

uint32_t aa_display_dirty_count(void)
{
	uint32_t count = 0;

	for (uint32_t mb = 0; mb < AA_MBS; mb++) {
		if (atomic_test_bit(aa_dirty, mb)) {
			count++;
		}
	}

	return count;
}

static int aa_display_write(const struct device *dev, const uint16_t x, const uint16_t y,
			    const struct display_buffer_descriptor *desc, const void *buf)
{
	const uint8_t *src = buf;
	size_t src_stride = (size_t)desc->pitch * AA_BPP;
	bool changed = false;

	if (desc->width > desc->pitch || (x + desc->width) > AA_LV_W ||
	    (y + desc->height) > AA_LV_H || desc->buf_size < src_stride * desc->height) {
		LOG_ERR("Invalid write %ux%u at %u,%u pitch %u size %u", desc->width,
			desc->height, x, y, desc->pitch, desc->buf_size);
		return -EINVAL;
	}

	for (uint32_t row = 0; row < desc->height; row++) {
		uint32_t fb_row = y + row;
		uint8_t *dst = &aa_fb[(fb_row * AA_LV_W + x) * AA_BPP];
		const uint8_t *s = src + row * src_stride;
		uint32_t mb_row = (fb_row * AA_SCALE) / 16U;
		uint32_t col = x;
		uint32_t end = x + desc->width;

		while (col < end) {
			uint32_t mb_col = (col * AA_SCALE) / 16U;
			uint32_t seg_end = MIN((mb_col + 1U) * AA_MB_LV_PX, end);
			size_t off = (col - x) * AA_BPP;
			size_t len = (seg_end - col) * AA_BPP;

			if (!IS_ENABLED(CONFIG_SAMPLE_AA_DIRTY_COMPARE) ||
			    memcmp(dst + off, s + off, len) != 0) {
				memcpy(dst + off, s + off, len);
				atomic_set_bit(aa_dirty, mb_row * AA_MBS_X + mb_col);
				changed = true;
			}
			col = seg_end;
		}
	}

	if (changed) {
		atomic_set(&aa_dirty_since_frame, 1);
	}

	if (!desc->frame_incomplete && atomic_cas(&aa_dirty_since_frame, 1, 0)) {
		k_sem_give(&aa_frame_sem);
	}

	return 0;
}

static int aa_display_blanking(const struct device *dev)
{
	return 0;
}

static void aa_display_get_capabilities(const struct device *dev,
					struct display_capabilities *caps)
{
	memset(caps, 0, sizeof(*caps));
	caps->x_resolution = AA_LV_W;
	caps->y_resolution = AA_LV_H;
	if (IS_ENABLED(CONFIG_SAMPLE_AA_PIXEL_L8)) {
		caps->supported_pixel_formats = PIXEL_FORMAT_L_8;
		caps->current_pixel_format = PIXEL_FORMAT_L_8;
	} else {
		caps->supported_pixel_formats = PIXEL_FORMAT_RGB_565;
		caps->current_pixel_format = PIXEL_FORMAT_RGB_565;
	}
	caps->current_orientation = DISPLAY_ORIENTATION_NORMAL;
}

static int aa_display_set_pixel_format(const struct device *dev,
				       const enum display_pixel_format format)
{
	struct display_capabilities caps;

	aa_display_get_capabilities(dev, &caps);

	return (format == caps.current_pixel_format) ? 0 : -ENOTSUP;
}

static int aa_display_init(const struct device *dev)
{
	LOG_INF("Virtual display %ux%u (%s), stream %ux%u, scale %u", AA_LV_W, AA_LV_H,
		IS_ENABLED(CONFIG_SAMPLE_AA_PIXEL_L8) ? "L8" : "RGB565", AA_VIDEO_WIDTH,
		AA_VIDEO_HEIGHT, AA_SCALE);

	return 0;
}

static DEVICE_API(display, aa_display_api) = {
	.blanking_on = aa_display_blanking,
	.blanking_off = aa_display_blanking,
	.write = aa_display_write,
	.get_capabilities = aa_display_get_capabilities,
	.set_pixel_format = aa_display_set_pixel_format,
};

DEVICE_DT_INST_DEFINE(0, aa_display_init, NULL, NULL, NULL, POST_KERNEL,
		      CONFIG_DISPLAY_INIT_PRIORITY, &aa_display_api);
```

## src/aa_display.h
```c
/*
 * Copyright The Zephyr Project Contributors
 * SPDX-License-Identifier: Apache-2.0
 */

#ifndef SAMPLES_SUBSYS_USB_ANDROID_AUTO_SRC_AA_DISPLAY_H_
#define SAMPLES_SUBSYS_USB_ANDROID_AUTO_SRC_AA_DISPLAY_H_

#include <stdint.h>

#include <zephyr/kernel.h>
#include <zephyr/sys/atomic.h>

/* Stream geometry, shared by the display, the encoder and the protocol */
#define AA_VIDEO_WIDTH  CONFIG_SAMPLE_AA_VIDEO_WIDTH
#define AA_VIDEO_HEIGHT CONFIG_SAMPLE_AA_VIDEO_HEIGHT
#define AA_MBS_X        (AA_VIDEO_WIDTH / 16)
#define AA_MBS_Y        (AA_VIDEO_HEIGHT / 16)
#define AA_MBS          (AA_MBS_X * AA_MBS_Y)

struct aa_display_geometry {
	/** Framebuffer (LVGL) resolution */
	uint16_t lv_width;
	uint16_t lv_height;
	/** Stream resolution */
	uint16_t width;
	uint16_t height;
	/** Stream pixels per framebuffer pixel, 1 or 2 */
	uint8_t scale;
	/** Framebuffer bytes per pixel: 2 for RGB565, 1 for L8 */
	uint8_t bpp;
	uint16_t mbs_x;
	uint16_t mbs_y;
};

/** @brief Geometry of the virtual display. */
const struct aa_display_geometry *aa_display_geometry(void);

/** @brief Framebuffer holding the last rendered LVGL screen (row-major). */
const uint8_t *aa_display_framebuffer(void);

/**
 * @brief Dirty macroblock bitmap in stream macroblock raster order.
 *
 * Bits are set by the display driver after the framebuffer was updated and
 * cleared by the encoder when it captures a macroblock.
 */
atomic_t *aa_display_dirty(void);

/**
 * @brief Wait until an LVGL refresh cycle changed the framebuffer.
 *
 * @retval 0 A completed refresh left dirty macroblocks.
 * @retval -EAGAIN Timeout.
 */
int aa_display_wait_frame(k_timeout_t timeout);

/** @brief Number of dirty macroblocks. */
uint32_t aa_display_dirty_count(void);

#endif /* SAMPLES_SUBSYS_USB_ANDROID_AUTO_SRC_AA_DISPLAY_H_ */
```

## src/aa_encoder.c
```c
/*
 * Copyright The Zephyr Project Contributors
 * SPDX-License-Identifier: Apache-2.0
 */

#include "aa_encoder.h"

#include <errno.h>
#include <string.h>

#include <zephyr/kernel.h>
#include <zephyr/logging/log.h>

#include "yuv.h"

LOG_MODULE_REGISTER(aa_encoder, CONFIG_SAMPLE_AA_LOG_LEVEL);

/*
 * Frame production: the dirty macroblocks left by LVGL refreshes are captured
 * (clearing their dirty bits), the picture is measured with a null sink so
 * that the messenger knows the access unit size up front, then converted and
 * emitted. Macroblocks that change while a picture is emitted are re-marked
 * dirty by the display driver and go out with the next picture.
 */

static struct h264_ipcm_enc enc;
static uint8_t stage[CONFIG_SAMPLE_AA_H264_OUT_BUF_SIZE];
static bool need_idr = true;
static size_t sps_pps_len;

static struct {
	struct aa_video_stats pub;
	int64_t win_start;
	uint32_t win_frames;
	uint64_t win_bytes;
} stats;

int aa_encoder_init(void)
{
	const struct aa_display_geometry *g = aa_display_geometry();
	const struct h264_ipcm_cfg cfg = {
		.width_mbs = g->mbs_x,
		.height_mbs = g->mbs_y,
		.level_idc = CONFIG_SAMPLE_AA_H264_LEVEL_IDC,
		.mb_rows_per_slice = CONFIG_SAMPLE_AA_H264_SLICE_ROWS,
	};
	int ret;

	ret = h264_ipcm_init(&enc, &cfg, stage, sizeof(stage));
	if (ret != 0) {
		return ret;
	}

	ret = h264_ipcm_write_sps_pps(&enc, NULL, NULL);
	if (ret < 0) {
		return ret;
	}

	sps_pps_len = (size_t)ret;
	need_idr = true;
	memset(&stats, 0, sizeof(stats));
	stats.win_start = k_uptime_get();

	LOG_INF("H.264 %ux%u, %u macroblocks, %u rows per slice, SPS+PPS %zu bytes", g->width,
		g->height, AA_MBS, CONFIG_SAMPLE_AA_H264_SLICE_ROWS, sps_pps_len);

	return 0;
}

void aa_encoder_reset(void)
{
	h264_ipcm_reset(&enc);
	need_idr = true;
}

size_t aa_encoder_config_len(void)
{
	return sps_pps_len;
}

int aa_encoder_write_config(aa_video_sink_t sink, void *ctx)
{
	return h264_ipcm_write_sps_pps(&enc, sink, ctx);
}

void aa_encoder_convert_mb(uint32_t mb, uint8_t *pcm)
{
	const struct aa_display_geometry *g = aa_display_geometry();
	const uint8_t *fb = aa_display_framebuffer();
	uint32_t mb_px = 16U / g->scale;
	uint32_t px = (mb % g->mbs_x) * mb_px;
	uint32_t py = (mb / g->mbs_x) * mb_px;
	const uint8_t *src = &fb[(py * g->lv_width + px) * g->bpp];

	if (g->bpp == 2U) {
		if (g->scale == 1U) {
			yuv_mb_rgb565((const uint16_t *)src, g->lv_width, pcm);
		} else {
			yuv_mb_rgb565_x2((const uint16_t *)src, g->lv_width, pcm);
		}
	} else if (g->scale == 1U) {
		yuv_mb_l8(src, g->lv_width, pcm);
	} else {
		yuv_mb_l8_x2(src, g->lv_width, pcm);
	}
}

static int run_picture(const struct aa_frame_plan *plan, aa_video_sink_t sink, void *ctx)
{
	uint8_t pcm[H264_MB_BYTES];
	int ret;

	ret = h264_ipcm_begin_picture(&enc, plan->idr, sink, ctx);
	if (ret != 0) {
		return ret;
	}

	for (uint32_t mb = 0; mb < AA_MBS; mb++) {
		if (!atomic_test_bit(plan->mbs, mb)) {
			ret = h264_ipcm_skip_mb(&enc);
		} else if (sink == NULL) {
			ret = h264_ipcm_write_mb(&enc, NULL);
		} else {
			aa_encoder_convert_mb(mb, pcm);
			ret = h264_ipcm_write_mb(&enc, pcm);
		}

		if (ret != 0) {
			(void)h264_ipcm_end_picture(&enc);
			return ret;
		}
	}

	return h264_ipcm_end_picture(&enc);
}

int aa_encoder_prepare(bool force_idr, struct aa_frame_plan *plan)
{
	atomic_t *dirty = aa_display_dirty();
	uint32_t max_mbs = CONFIG_SAMPLE_AA_MAX_MBS_PER_FRAME;
	int ret;

	memset(plan, 0, sizeof(*plan));
	plan->idr = force_idr || need_idr;

	for (uint32_t mb = 0; mb < AA_MBS; mb++) {
		if (plan->idr) {
			atomic_clear_bit(dirty, mb);
			atomic_set_bit(plan->mbs, mb);
			plan->coded_mbs++;
		} else if (atomic_test_bit(dirty, mb)) {
			if (max_mbs == 0U || plan->coded_mbs < max_mbs) {
				atomic_clear_bit(dirty, mb);
				atomic_set_bit(plan->mbs, mb);
				plan->coded_mbs++;
			} else {
				plan->pending_mbs++;
			}
		}
	}

	if (plan->coded_mbs == 0U) {
		return -EAGAIN;
	}

	ret = run_picture(plan, NULL, NULL);
	if (ret < 0) {
		LOG_ERR("Measuring the picture failed (%d)", ret);
		aa_encoder_reset();
		return -EIO;
	}

	plan->au_len = (size_t)ret + (plan->idr ? sps_pps_len : 0U);

	return 0;
}

static void stats_update(bool idr, size_t bytes, uint32_t encode_us, uint32_t pending)
{
	int64_t now = k_uptime_get();
	int64_t elapsed = now - stats.win_start;

	stats.pub.frames++;
	if (idr) {
		stats.pub.idr_frames++;
	}
	stats.pub.bytes += bytes;
	stats.pub.last_encode_us = encode_us;
	stats.pub.pending_mbs = pending;
	stats.win_frames++;
	stats.win_bytes += bytes;

	if (elapsed >= 1000) {
		stats.pub.fps_x10 = (uint32_t)((stats.win_frames * 10000ULL) / (uint64_t)elapsed);
		stats.pub.kbit_s = (uint32_t)((stats.win_bytes * 8ULL) / (uint64_t)elapsed);
		stats.win_start = now;
		stats.win_frames = 0U;
		stats.win_bytes = 0U;
	}
}

int aa_encoder_emit(const struct aa_frame_plan *plan, aa_video_sink_t sink, void *ctx)
{
	uint32_t t0 = k_cycle_get_32();
	size_t total = 0;
	int ret;

	if (plan->idr) {
		ret = h264_ipcm_write_sps_pps(&enc, sink, ctx);
		if (ret < 0) {
			goto error;
		}
		total += (size_t)ret;
	}

	ret = run_picture(plan, sink, ctx);
	if (ret < 0) {
		goto error;
	}
	total += (size_t)ret;

	if (total != plan->au_len) {
		LOG_ERR("Access unit is %zu bytes, %zu measured", total, plan->au_len);
		ret = -EIO;
		goto error;
	}

	stats_update(plan->idr, total, k_cyc_to_us_floor32(k_cycle_get_32() - t0),
		     plan->pending_mbs);
	if (plan->idr) {
		need_idr = false;
	}

	return 0;

error:
	aa_encoder_reset();
	return ret;
}

void aa_encoder_get_stats(struct aa_video_stats *out)
{
	*out = stats.pub;
	if ((k_uptime_get() - stats.win_start) > 2000) {
		out->fps_x10 = 0U;
		out->kbit_s = 0U;
	}
}
```

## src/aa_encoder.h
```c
/*
 * Copyright The Zephyr Project Contributors
 * SPDX-License-Identifier: Apache-2.0
 */

#ifndef SAMPLES_SUBSYS_USB_ANDROID_AUTO_SRC_AA_ENCODER_H_
#define SAMPLES_SUBSYS_USB_ANDROID_AUTO_SRC_AA_ENCODER_H_

#include <stdbool.h>
#include <stddef.h>
#include <stdint.h>

#include <zephyr/sys/atomic.h>

#include "aa_display.h"
#include "h264_ipcm.h"

/** Access unit byte sink, called with at most CONFIG_SAMPLE_AA_H264_OUT_BUF_SIZE bytes. */
typedef h264_sink_t aa_video_sink_t;

/** Macroblocks captured for one picture and the exact size it will produce. */
struct aa_frame_plan {
	bool idr;
	ATOMIC_DEFINE(mbs, AA_MBS);
	uint32_t coded_mbs;
	uint32_t pending_mbs;
	size_t au_len;
};

struct aa_video_stats {
	uint32_t frames;
	uint32_t idr_frames;
	uint64_t bytes;
	uint32_t fps_x10;
	uint32_t kbit_s;
	uint32_t last_encode_us;
	uint32_t pending_mbs;
};

/**
 * @brief Initialize the encoder for the configured stream geometry.
 *
 * @retval 0 Success.
 * @retval -EINVAL Invalid geometry.
 */
int aa_encoder_init(void);

/** @brief Force the next picture to be an IDR picture of the whole screen. */
void aa_encoder_reset(void);

/** @brief Size in bytes of the SPS and PPS NAL units. */
size_t aa_encoder_config_len(void);

/**
 * @brief Write the SPS and PPS NAL units.
 *
 * @return Bytes written or a negative errno from the sink.
 */
int aa_encoder_write_config(aa_video_sink_t sink, void *ctx);

/**
 * @brief Capture the dirty macroblocks and measure the resulting access unit.
 *
 * @param force_idr Code the whole screen as an IDR picture.
 * @param plan Filled with the captured macroblocks and the access unit size.
 *
 * @retval 0 A picture is ready to be emitted.
 * @retval -EAGAIN Nothing changed since the last picture.
 * @retval -EIO Encoder error.
 */
int aa_encoder_prepare(bool force_idr, struct aa_frame_plan *plan);

/**
 * @brief Encode the planned picture and push exactly plan->au_len bytes to the sink.
 *
 * On failure the sequence is reset and the next picture is an IDR picture.
 *
 * @retval 0 Success.
 * @retval -EIO The emitted size differs from the measured one.
 * @return Negative errno returned by the sink.
 */
int aa_encoder_emit(const struct aa_frame_plan *plan, aa_video_sink_t sink, void *ctx);

/** @brief Copy the current statistics. */
void aa_encoder_get_stats(struct aa_video_stats *stats);

/** @brief Convert stream macroblock mb from the framebuffer into I_PCM samples. */
void aa_encoder_convert_mb(uint32_t mb, uint8_t *pcm);

#endif /* SAMPLES_SUBSYS_USB_ANDROID_AUTO_SRC_AA_ENCODER_H_ */
```
